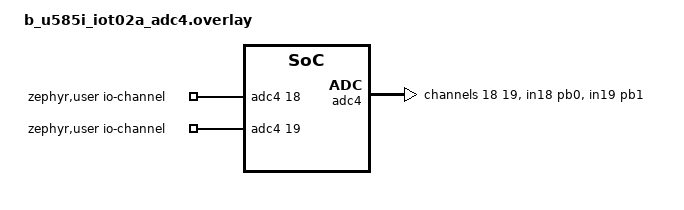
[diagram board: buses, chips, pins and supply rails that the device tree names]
/*
 * SPDX-License-Identifier: Apache-2.0
 *
 * Copyright (c) 2023 STMicroelectronics
 */

/ {
	zephyr,user {
		/* adjust channel number according to pinmux in board.dts */
		io-channels = <&adc4 18>, <&adc4 19>;
	};
};

&adc4 {
	pinctrl-0 = <&adc4_in18_pb0 &adc4_in19_pb1>;
	#address-cells = <1>;
	#size-cells = <0>;

	channel@12 {
		reg = <18>;
		zephyr,gain = "ADC_GAIN_1";
		zephyr,reference = "ADC_REF_INTERNAL";
		zephyr,acquisition-time = <ADC_ACQ_TIME_MAX>;
		zephyr,resolution = <12>;
	};

	channel@13 {
		reg = <19>;
		zephyr,gain = "ADC_GAIN_1";
		zephyr,reference = "ADC_REF_INTERNAL";
		zephyr,acquisition-time = <ADC_ACQ_TIME_MAX>;
		zephyr,resolution = <12>;
	};
};

&adc1 {
	status = "disabled";
};
